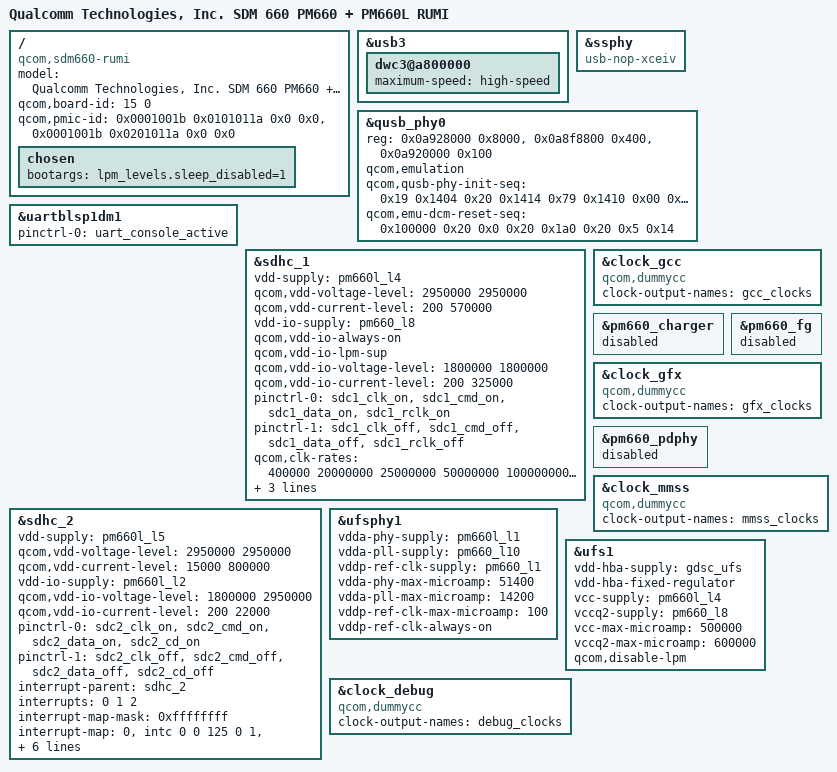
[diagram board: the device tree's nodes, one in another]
/* Copyright (c) 2016-2017, The Linux Foundation. All rights reserved.
 *
 * This program is free software; you can redistribute it and/or modify
 * it under the terms of the GNU General Public License version 2 and
 * only version 2 as published by the Free Software Foundation.
 *
 * This program is distributed in the hope that it will be useful,
 * but WITHOUT ANY WARRANTY; without even the implied warranty of
 * MERCHANTABILITY or FITNESS FOR A PARTICULAR PURPOSE.  See the
 * GNU General Public License for more details.
 */


/dts-v1/;

#include "sdm660.dtsi"
#include "sdm660-pinctrl.dtsi"

/ {
	model = "Qualcomm Technologies, Inc. SDM 660 PM660 + PM660L RUMI";
	compatible = "qcom,sdm660-rumi", "qcom,sdm660", "qcom,rumi";
	qcom,board-id = <15 0>;
	qcom,pmic-id = <0x0001001b 0x0101011a 0x0 0x0>,
			<0x0001001b 0x0201011a 0x0 0x0>;

	chosen {
		bootargs = "lpm_levels.sleep_disabled=1";
	};
};

&usb3 {
	/delete-property/ USB3_GDSC-supply;
	/delete-property/ extcon;
	dwc3@a800000 {
		maximum-speed = "high-speed";
	};
};

&ssphy {
	compatible =  "usb-nop-xceiv";
};

&qusb_phy0 {
	reg = <0x0a928000 0x8000>,
		<0x0a8f8800 0x400>,
		<0x0a920000 0x100>;
		reg-names = "qusb_phy_base",
			"qscratch_base",
			"emu_phy_base";
		qcom,emulation;
		qcom,qusb-phy-init-seq = <0x19 0x1404
					0x20 0x1414
					0x79 0x1410
					0x00 0x1418
					0x99 0x1404
					0x04 0x1408
					0xd9 0x1404>;
		qcom,emu-dcm-reset-seq = <0x100000 0x20
					0x0 0x20
					0x1a0 0x20
					0x5 0x14>;
};

&uartblsp1dm1 {
	status = "ok";
	pinctrl-names = "default";
	pinctrl-0 = <&uart_console_active>;
};

&sdhc_1 {
	/* device core power supply */
	vdd-supply = <&pm660l_l4>;
	qcom,vdd-voltage-level = <2950000 2950000>;
	qcom,vdd-current-level = <200 570000>;

	/* device communication power supply */
	vdd-io-supply = <&pm660_l8>;
	qcom,vdd-io-always-on;
	qcom,vdd-io-lpm-sup;
	qcom,vdd-io-voltage-level = <1800000 1800000>;
	qcom,vdd-io-current-level = <200 325000>;

	pinctrl-names = "active", "sleep";
	pinctrl-0 = <&sdc1_clk_on &sdc1_cmd_on &sdc1_data_on &sdc1_rclk_on>;
	pinctrl-1 = <&sdc1_clk_off &sdc1_cmd_off &sdc1_data_off &sdc1_rclk_off>;

	qcom,clk-rates = <400000 20000000 25000000 50000000 100000000 192000000
								384000000>;

	qcom,nonremovable;
	qcom,bus-speed-mode = "HS400_1p8v", "HS200_1p8v", "DDR_1p8v";

	status = "ok";
};

&sdhc_2 {
	/* device core power supply */
	vdd-supply = <&pm660l_l5>;
	qcom,vdd-voltage-level = <2950000 2950000>;
	qcom,vdd-current-level = <15000 800000>;

	/* device communication power supply */
	vdd-io-supply = <&pm660l_l2>;
	qcom,vdd-io-voltage-level = <1800000 2950000>;
	qcom,vdd-io-current-level = <200 22000>;

	pinctrl-names = "active", "sleep";
	pinctrl-0 = <&sdc2_clk_on &sdc2_cmd_on &sdc2_data_on &sdc2_cd_on>;
	pinctrl-1 = <&sdc2_clk_off &sdc2_cmd_off &sdc2_data_off &sdc2_cd_off>;

	#address-cells = <0>;
	interrupt-parent = <&sdhc_2>;
	interrupts = <0 1 2>;
	#interrupt-cells = <1>;
	interrupt-map-mask = <0xffffffff>;
	interrupt-map = <0 &intc 0 0 125 0
			1 &intc 0 0 221 0
			2 &tlmm 54 0>;
	interrupt-names = "hc_irq", "pwr_irq", "status_irq";
	cd-gpios = <&tlmm 54 0x1>;

	qcom,clk-rates = <400000 20000000 25000000 50000000 100000000
								200000000>;
	qcom,bus-speed-mode = "SDR12", "SDR25", "SDR50", "DDR50", "SDR104";

	status = "ok";
};

&clock_gcc {
	compatible = "qcom,dummycc";
	clock-output-names = "gcc_clocks";
};

&pm660_charger {
	status = "disabled";
};

&pm660_fg {
	status = "disabled";
};

&clock_gfx {
	compatible = "qcom,dummycc";
	clock-output-names = "gfx_clocks";
};

&pm660_pdphy {
	status = "disabled";
};

&clock_mmss {
	compatible = "qcom,dummycc";
	clock-output-names = "mmss_clocks";
};

&ufsphy1 {
	vdda-phy-supply = <&pm660l_l1>;
	vdda-pll-supply = <&pm660_l10>;
	vddp-ref-clk-supply = <&pm660_l1>;
	vdda-phy-max-microamp = <51400>;
	vdda-pll-max-microamp = <14200>;
	vddp-ref-clk-max-microamp = <100>;
	vddp-ref-clk-always-on;
};

&ufs1 {
	vdd-hba-supply = <&gdsc_ufs>;
	vdd-hba-fixed-regulator;
	vcc-supply = <&pm660l_l4>;
	vccq2-supply = <&pm660_l8>;
	vcc-max-microamp = <500000>;
	vccq2-max-microamp = <600000>;
	qcom,disable-lpm;
};

&clock_debug {
	compatible = "qcom,dummycc";
	clock-output-names = "debug_clocks";
};
